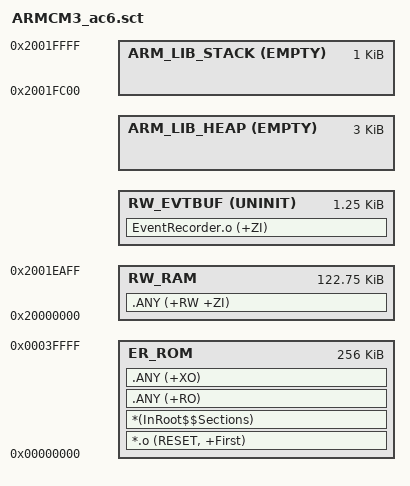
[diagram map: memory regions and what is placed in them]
#! armclang -E --target=arm-arm-none-eabi -mcpu=cortex-m3 -xc
; command above MUST be in first line (no comment above!)

/*
;-------- <<< Use Configuration Wizard in Context Menu >>> -------------------
*/

/*--------------------- Flash Configuration ----------------------------------
; <h> Flash Configuration
;   <o0> Flash Base Address <0x0-0xFFFFFFFF:8>
;   <o1> Flash Size (in Bytes) <0x0-0xFFFFFFFF:8>
; </h>
 *----------------------------------------------------------------------------*/
#define __ROM_BASE      0x00000000
#define __ROM_SIZE      0x00040000

/*--------------------- Embedded RAM Configuration ---------------------------
; <h> RAM Configuration
;   <o0> RAM Base Address    <0x0-0xFFFFFFFF:8>
;   <o1> RAM Size (in Bytes) <0x0-0xFFFFFFFF:8>
; </h>
 *----------------------------------------------------------------------------*/
#define __RAM_BASE      0x20000000
#define __RAM_SIZE      0x00020000

/*--------------------- Stack / Heap Configuration ---------------------------
; <h> Stack / Heap Configuration
;   <o0> Stack Size (in Bytes) <0x0-0xFFFFFFFF:8>
;   <o1> Heap Size (in Bytes) <0x0-0xFFFFFFFF:8>
; </h>
 *----------------------------------------------------------------------------*/
#define __STACK_SIZE    0x00000400
#define __HEAP_SIZE     0x00000C00

/*--------------------- EventRecorder Configuration --------------------------*/
; <e> EventRecorder Configuration
#define __EVT_ENABLE    1

;   <o> Number of Records
;     <8=>8 <16=>16 <32=>32 <64=>64 <128=>128 <256=>256 <512=>512 <1024=>1024
;     <2048=>2048 <4096=>4096 <8192=>8192 <16384=>16384 <32768=>32768
;     <65536=>65536
#define __EVT_RECORDS   64

; </e>

/*
;------------- <<< end of configuration section >>> ---------------------------
*/


/*----------------------------------------------------------------------------
  User Stack & Heap boundary definition
 *----------------------------------------------------------------------------*/
#define __STACK_TOP    (__RAM_BASE + __RAM_SIZE)    /* starts at end of RAM */
#define __HEAP_BASE    (AlignExpr(+0, 8))           /* starts after RW_RAM section, 8 byte aligned */


/*----------------------------------------------------------------------------
  Scatter File Definitions definition
 *----------------------------------------------------------------------------*/
#ifdef __EVT_ENABLE
#define __EVBUF_SIZE   (256 + __EVT_RECORDS*16)
#define __EVBUF_BASE   (AlignExpr(+0, 8))           /* starts after RW_RAM section, 8 byte aligned */
#else
#define __EVBUF_SIZE    0
#endif

#define __RO_BASE       __ROM_BASE
#define __RO_SIZE       __ROM_SIZE

#define __RW_BASE       __RAM_BASE
#define __RW_SIZE      (__RAM_SIZE - __STACK_SIZE - __HEAP_SIZE - __EVBUF_SIZE)


LR_ROM __RO_BASE __RO_SIZE  {                       ; load region size_region
  ER_ROM __RO_BASE __RO_SIZE  {                     ; load address = execution address
   *.o (RESET, +First)
   *(InRoot$$Sections)
   .ANY (+RO)
   .ANY (+XO)
  }

  RW_RAM __RW_BASE __RW_SIZE  {                     ; RW data
   .ANY (+RW +ZI)
  }

#ifdef __EVT_ENABLE
  RW_EVTBUF __EVBUF_BASE UNINIT __EVBUF_SIZE {      ; Uninitialized region for Event Buffer
    EventRecorder.o (+ZI)
  }
#endif

#if __HEAP_SIZE > 0
  ARM_LIB_HEAP  __HEAP_BASE EMPTY  __HEAP_SIZE  {   ; Reserve empty region for heap
  }
#endif

  ARM_LIB_STACK __STACK_TOP EMPTY -__STACK_SIZE {   ; Reserve empty region for stack
  }
}
